# STM32G0B1 register map
File version: 1.8
CPU: CM0 r0p1, little endian, MPU, no FPU, 4 interrupt priority bits
Registers are 32-bit, read-write, reset 0x0 unless marked. A register's access mark holds for its fields unless they carry their own. Offsets are from the block's base; [hi:lo] are bit positions; {n}, {i} and the like mark numbered series.

## TAMP — Tamper and backup registers
Base 0x4000B000
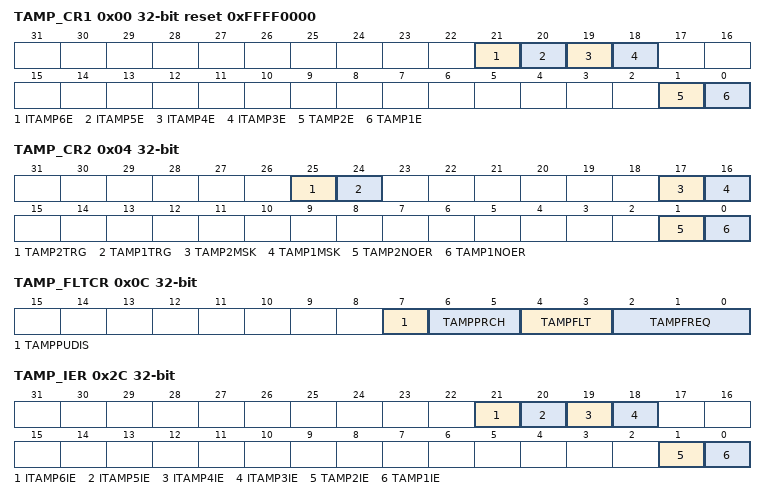
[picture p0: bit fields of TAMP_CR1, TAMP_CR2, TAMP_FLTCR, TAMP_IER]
0x00 TAMP_CR1 reset 0xFFFF0000 — TAMP control register 1
  [21] ITAMP6E — Internal tamper 6 enable: ST manufacturer readout
    0=Internal tamper 6 disabled; 1=Internal tamper 6 enabled: a tamper is generated in case of ST manufacturer readout
  [20] ITAMP5E — Internal tamper 5 enable: RTC calendar overflow
    0=Internal tamper 5 disabled; 1=Internal tamper 5 enabled: a tamper is generated when the RTC calendar reaches its maximum value, on the 31st of December 99, at 23:59:59. The calendar is then frozen and cannot overflow.
  [19] ITAMP4E — Internal tamper 4 enable: HSE monitoring
    0=Internal tamper 4 disabled; 1=Internal tamper 4 enabled. a tamper is generated when the HSE frequency is below or above thresholds.
  [18] ITAMP3E — Internal tamper 3 enable: LSE monitoring
    0=Internal tamper 3 disabled; 1=Internal tamper 3 enabled: a tamper is generated when the LSE frequency is below or above thresholds
  [1] TAMP2E — Tamper detection on TAMP_IN2 enable
    0=Tamper detection on TAMP_IN2 is disabled; 1=Tamper detection on TAMP_IN2 is enabled
  [0] TAMP1E — Tamper detection on TAMP_IN1 enable
    0=Tamper detection on TAMP_IN1 is disabled; 1=Tamper detection on TAMP_IN1 is enabled
0x04 TAMP_CR2 — TAMP control register 2
  [25] TAMP2TRG — Active level for tamper 2 input (active mode disabled) If TAMPFLT = 00 Tamper 2 input rising edge and high level triggers a tamper detection event. If TAMPFLT = 00 Tamper 2 input falling edge and low level triggers a tamper detection event.
    0=If TAMPFLT diferent 00 Tamper 2 input staying low triggers a tamper detection event; 1=If TAMPFLT = 00 Tamper 2 input staying high triggers a tamper detection event
  [24] TAMP1TRG — Active level for tamper 1 input (active mode disabled) If TAMPFLT = 00 Tamper 1 input rising edge and high level triggers a tamper detection event. If TAMPFLT = 00 Tamper 1 input falling edge and low level triggers a tamper detection event.
    0=If TAMPFLT diferent 00 Tamper 1 input staying low triggers a tamper detection event; 1=If TAMPFLT = 00 Tamper 1 input staying high triggers a tamper detection event
  [17] TAMP2MSK — Tamper 2 mask The tamper 2 interrupt must not be enabled when TAMP2MSK is set.
    0=Tamper 2 event generates a trigger event and TAMP2F must be cleared by software to allow next tamper event detection; 1=Tamper 2 event generates a trigger event. TAMP2F is masked and internally cleared by hardware. The backup registers are not erased.
  [16] TAMP1MSK — Tamper 1 mask The tamper 1 interrupt must not be enabled when TAMP1MSK is set.
    0=Tamper 1 event generates a trigger event and TAMP1F must be cleared by software to allow next tamper event detection; 1=Tamper 1 event generates a trigger event. TAMP1F is masked and internally cleared by hardware. The backup registers are not erased.
  [1] TAMP2NOER — Tamper 2 no erase
    0=Tamper 2 event erases the backup registers; 1=Tamper 2 event does not erase the backup registers
  [0] TAMP1NOER — Tamper 1 no erase
    0=Tamper 1 event erases the backup registers; 1=Tamper 1 event does not erase the backup registers
0x0C TAMP_FLTCR — TAMP filter control register
  [7] TAMPPUDIS — TAMP_INx pull-up disable This bit determines if each of the TAMPx pins are precharged before each sample.
    0=Precharge TAMP_INx pins before sampling (enable internal pull-up); 1=Disable precharge of TAMP_INx pins
  [6:5] TAMPPRCH — TAMP_INx precharge duration These bit determines the duration of time during which the pull-up/is activated before each sample. TAMPPRCH is valid for each of the TAMP_INx inputs.
    0=1 RTCCLK cycle; 1=2 RTCCLK cycles; 2=4 RTCCLK cycles; 3=8 RTCCLK cycles
  [4:3] TAMPFLT — TAMP_INx filter count These bits determines the number of consecutive samples at the specified level (TAMP*TRG) needed to activate a tamper event. TAMPFLT is valid for each of the TAMP_INx inputs.
    0=Tamper event is activated on edge of TAMP_INx input transitions to the active level (no internal pull-up on TAMP_INx input); 1=Tamper event is activated after 2 consecutive samples at the active level; 2=Tamper event is activated after 4 consecutive samples at the active level; 3=Tamper event is activated after 8 consecutive samples at the active level
  [2:0] TAMPFREQ — Tamper sampling frequency Determines the frequency at which each of the TAMP_INx inputs are sampled.
    0=RTCCLK / 32768 (1 Hz when RTCCLK = 32768 Hz); 1=RTCCLK / 16384 (2 Hz when RTCCLK = 32768 Hz); 2=RTCCLK / 8192 (4 Hz when RTCCLK = 32768 Hz); 3=RTCCLK / 4096 (8 Hz when RTCCLK = 32768 Hz); 4=RTCCLK / 2048 (16 Hz when RTCCLK = 32768 Hz); 5=RTCCLK / 1024 (32 Hz when RTCCLK = 32768 Hz); 6=RTCCLK / 512 (64 Hz when RTCCLK = 32768 Hz); 7=RTCCLK / 256 (128 Hz when RTCCLK = 32768 Hz)
0x2C TAMP_IER — TAMP interrupt enable register
  [21] ITAMP6IE — Internal tamper 6 interrupt enable: ST manufacturer readout
    0=Internal tamper 6 interrupt disabled; 1=Internal tamper 6 interrupt enabled
  [20] ITAMP5IE — Internal tamper 5 interrupt enable: RTC calendar overflow
    0=Internal tamper 5 interrupt disabled; 1=Internal tamper 5 interrupt enabled
  [19] ITAMP4IE — Internal tamper 4 interrupt enable: HSE monitoring
    0=Internal tamper 4 interrupt disabled; 1=Internal tamper 4 interrupt enabled
  [18] ITAMP3IE — Internal tamper 3 interrupt enable: LSE monitoring
    0=Internal tamper 3 interrupt disabled; 1=Internal tamper 3 interrupt enabled
  [1] TAMP2IE — Tamper 2 interrupt enable
    0=Tamper 2 interrupt disabled; 1=Tamper 2 interrupt enabled
  [0] TAMP1IE — Tamper 1 interrupt enable
    0=Tamper 1 interrupt disabled; 1=Tamper 1 interrupt enabled
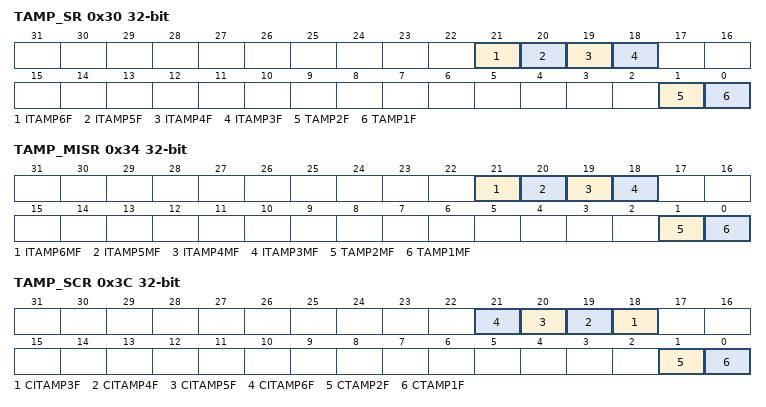
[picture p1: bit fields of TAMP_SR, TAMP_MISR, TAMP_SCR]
0x30 TAMP_SR ro — TAMP status register
  [21] ITAMP6F — ST manufacturer readout tamper detection flag This flag is set by hardware when a tamper detection event is detected on the internal tamper 6.
  [20] ITAMP5F — RTC calendar overflow tamper detection flag This flag is set by hardware when a tamper detection event is detected on the internal tamper 5.
  [19] ITAMP4F — HSE monitoring tamper detection flag This flag is set by hardware when a tamper detection event is detected on the internal tamper 4.
  [18] ITAMP3F — LSE monitoring tamper detection flag This flag is set by hardware when a tamper detection event is detected on the internal tamper 3.
  [1] TAMP2F — TAMP2 detection flag This flag is set by hardware when a tamper detection event is detected on the TAMP2 input.
  [0] TAMP1F — TAMP1 detection flag This flag is set by hardware when a tamper detection event is detected on the TAMP1 input.
0x34 TAMP_MISR ro — TAMP masked interrupt status register
  [21] ITAMP6MF — ST manufacturer readout tamper interrupt masked flag This flag is set by hardware when the internal tamper 6 interrupt is raised.
  [20] ITAMP5MF — RTC calendar overflow tamper interrupt masked flag This flag is set by hardware when the internal tamper 5 interrupt is raised.
  [19] ITAMP4MF — HSE monitoring tamper interrupt masked flag This flag is set by hardware when the internal tamper 4 interrupt is raised.
  [18] ITAMP3MF — LSE monitoring tamper interrupt masked flag This flag is set by hardware when the internal tamper 3 interrupt is raised.
  [1] TAMP2MF — TAMP2 interrupt masked flag This flag is set by hardware when the tamper 2 interrupt is raised.
  [0] TAMP1MF — TAMP1 interrupt masked flag This flag is set by hardware when the tamper 1 interrupt is raised.
0x3C TAMP_SCR wo — TAMP status clear register
  [n+15] CITAMP{n}F (n=3..6) — Clear ITAMP{n} detection flag Writing 1 in this bit clears the ITAMP{n}F bit in the TAMP_SR register.
  [1] CTAMP2F — Clear TAMP2 detection flag Writing 1 in this bit clears the TAMP2F bit in the TAMP_SR register.
  [0] CTAMP1F — Clear TAMP1 detection flag Writing 1 in this bit clears the TAMP1F bit in the TAMP_SR register.
{0x100+4i} TAMP_BKP{i}R (i=0..4) — TAMP backup {i} register
  [31:0] BKP — The application can write or read data to and from these registers. They are powered-on by VBAT when VDD is switched off, so that they are not reset by System reset, and their contents remain valid when the device operates in low-power mode. In the default configuration this register is reset on a tamper detection event. It is forced to reset value as long as there is at least one internal or external tamper flag being set. This register is also reset when the readout protection (RDP) is disabled.
